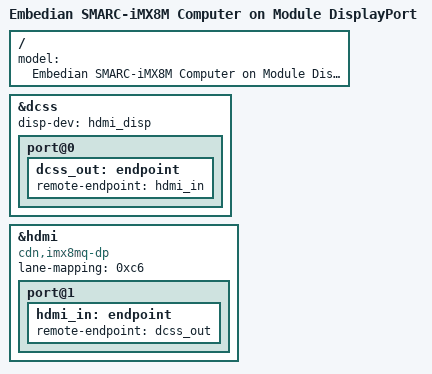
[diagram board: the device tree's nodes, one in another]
// SPDX-License-Identifier: (GPL-2.0 OR MIT)
/*
 * Copyright 2017 NXP
 * Copyright 2020 Embedian, Inc.
 * Copyright (C) 2017-2018 Pengutronix, Lucas Stach <kernel@pengutronix.de>
 */

#include "imx8mq-smarc-common.dtsi"
#include "imx8mq-smarc-hdmi.dtsi"

/ {
        model = "Embedian SMARC-iMX8M Computer on Module DisplayPort";
};

&dcss {
        status = "okay";
        disp-dev = "hdmi_disp";

        port@0 {
                dcss_out: endpoint {
                        remote-endpoint = <&hdmi_in>;
                };
        };
};

&hdmi {
        compatible = "cdn,imx8mq-dp";
        lane-mapping = <0xc6>;

        status = "okay";

        port@1 {
                hdmi_in: endpoint {
                        remote-endpoint = <&dcss_out>;
                };
        };
};
